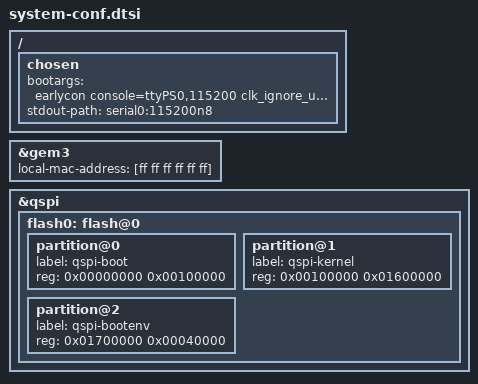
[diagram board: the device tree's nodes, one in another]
/*
 * CAUTION: This file is automatically generated by PetaLinux SDK.
 * DO NOT modify this file
 */


/ {
	chosen {
		bootargs = "earlycon console=ttyPS0,115200 clk_ignore_unused root=/dev/mmcblk0p2 ro rootwait uio_pdrv_genirq.of_id=generic-uio";
		stdout-path = "serial0:115200n8";
	};
};

&gem3 {
	local-mac-address = [ff ff ff ff ff ff];
};

&qspi {
	#address-cells = <1>;
	#size-cells = <0>;
	flash0: flash@0 {
		partition@0 {
			label = "qspi-boot";
			reg = <0x00000000 0x00100000>;
		};
		partition@1 {
			label = "qspi-kernel";
			reg = <0x00100000 0x01600000>;
		};
		partition@2 {
			label = "qspi-bootenv";
			reg = <0x01700000 0x00040000>;
		};
	};
};

